# a31g22x register map
Vendor: ABOV Semiconductor Co., Ltd.; Series: a31g22x; File version: 0.2
CPU: CM0PLUS r0p1, little endian, no MPU, no FPU, VTOR, 2 interrupt priority bits
Registers are 32-bit, read-write, reset 0x0 unless marked. A register's access mark holds for its fields unless they carry their own. Offsets are from the block's base; [hi:lo] are bit positions; {n}, {i} and the like mark numbered series.

## SCULV — Low Voltage Detector Indicator and Reset moudle
Base 0x40005100
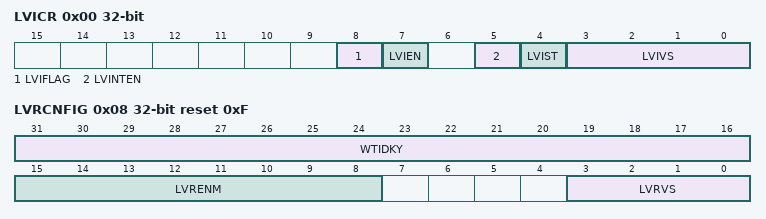
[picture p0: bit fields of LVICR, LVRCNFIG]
0x00 LVICR (reset mask 0xBF) — Low Voltage Indicator Control Register
  [8] LVIFLAG — LVI Interrupt Flag bit. This bit is clear by writing '1' to this bit.
  [7] LVIEN — LVI Enable bit
  [5] LVINTEN — LVI Interrupt Enable bit
  [4] LVIST ro — LVI Interrupt Status Flag bit. This bit is cleared to '0' when VDDEXT level is over than LVI level.
  [3:0] LVIVS — LVI Voltage Selection bits
0x04 LVRCR — Low Voltage Reset Control Register
  [7:0] LVREN — LVR Enable bits. These bits are cleared to 0x0 by POR and retained by other reset signals.
0x08 LVRCNFIG reset 0xF — Configuration for Low Voltage Reset
  [31:16] WTIDKY wo — Write Identification Key On writes, write 0x72A5 to these bits, otherwise the write is ignored.
  [15:8] LVRENM — LVR Reset Operation Control Master Configuration
  [3:0] LVRVS — LVR Voltage Selection bits

## PA — GENERAL PORT
Base 0x40001000
Same registers: PB 0x40001100, PC 0x40001200, PD 0x40001300, PE 0x40001400
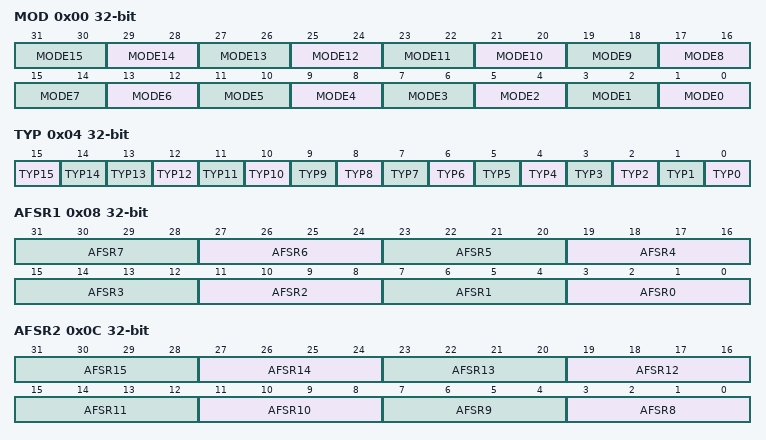
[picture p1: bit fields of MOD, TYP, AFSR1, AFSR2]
0x00 MOD — Port n Mode Register
  [2n+1:2n] MODE{n} (n=0..15) — Pin {n} Mode Selection bits
0x04 TYP — Port n Output Type Selection Register
  [15] TYP15 — Pin 15 Output Type Selection bit
  [14] TYP14 — Pin 15 Output Type Selection bit
  [n] TYP{n} (n=0..13) — Pin {n} Output Type Selection bit
0x08 AFSR1 — Port n Alternative Function Selection Register 1
  [4n+3:4n] AFSR{n} (n=0..7) — Pin {n} Alternative Function Selection bits
0x0C AFSR2 — Port n Alternative Function Selection Register 2
  [4n-29:4n-32] AFSR{n} (n=8..15) — Pin {n} Alternative Function Selection bits
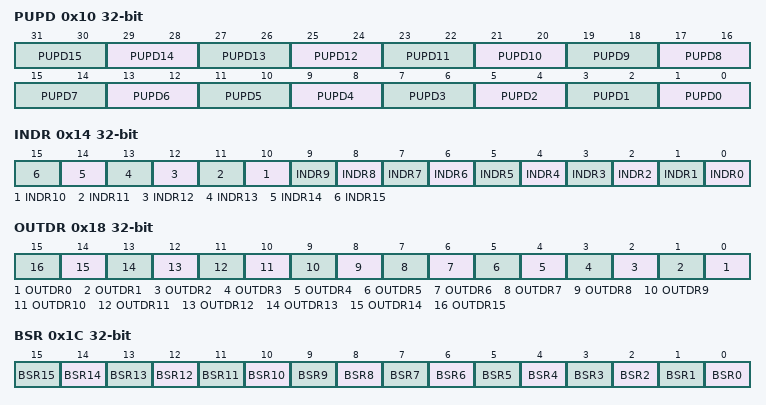
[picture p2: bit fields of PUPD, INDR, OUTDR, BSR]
0x10 PUPD — Port n Pull-up/down Resistor Selection Register
  [2n+1:2n] PUPD{n} (n=0..15) — Pin {n} Pull-up/down Resistor Selection bits
0x14 INDR ro — Port n Input Data Register
  [n] INDR{n} (n=0..15) — Pin {n} Input Data bit
0x18 OUTDR — Port n Output Data Register
  [n] OUTDR{n} (n=0..15) — Pin {n} Output Data bit
0x1C BSR wo — Port n Output Bit Set Register
  [n] BSR{n} (n=0..15) — Pin {n} Output Set bit. This bit is always read to 0
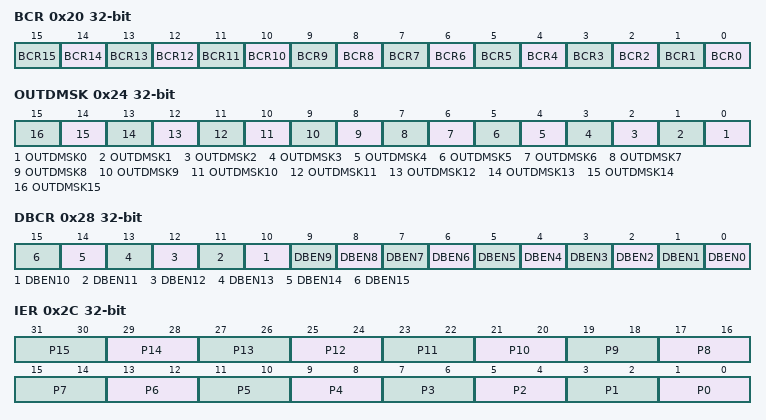
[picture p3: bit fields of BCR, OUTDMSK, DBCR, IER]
0x20 BCR wo — Port n Output Bit Clear Register
  [n] BCR{n} (n=0..15) — Pin {n} Output Clear bit. This bit is always read to 0.
0x24 OUTDMSK — Port n Output Data Mask Register
  [n] OUTDMSK{n} (n=0..15) — Pin {n} Output Data Mask bit
0x28 DBCR — Port n Debounce Control Register
  [n] DBEN{n} (n=0..15) — Pin {n} Debounce Enable bit
0x2C IER — Port n interrupt enable register
  [2n+1:2n] P{n} (n=0..15) — P{n} interrupt enable
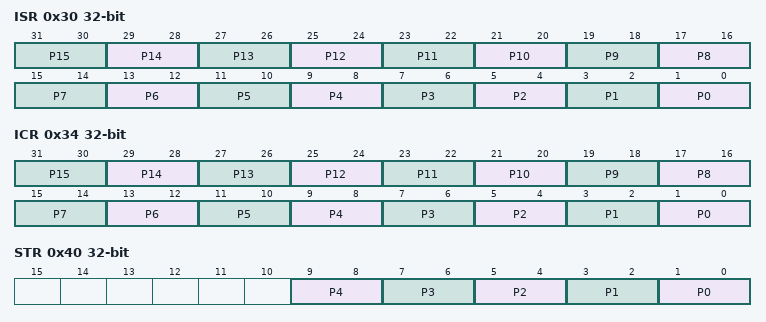
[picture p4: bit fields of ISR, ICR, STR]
0x30 ISR — Port n interrupt status register
  [2n+1:2n] P{n} (n=0..15) — P{n} interrupt status
0x34 ICR — Port n interrupt control register
  [2n+1:2n] P{n} (n=0..15) — P{n} interrupt control
0x40 STR — Port n Strength Configuration Register. This function is only valid for PB[2:0] and PC[4:2] ports.
  [2n+1:2n] P{n} (n=0..4) — P{n} Strength Configuration

## PF
Base 0x40001500
Registers as PA; these are added or differ:
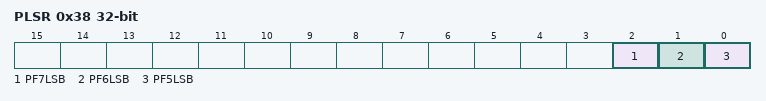
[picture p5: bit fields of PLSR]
0x38 PLSR — PORT F level select register
  [2] PF7LSB — PORTF 7 Level Select bit
  [1] PF6LSB — PORTF 6 Level Select bit
  [0] PF5LSB — PORTF 5 Level Select bit

## PCU1 — PORT CONTROL UNIT 1
Base 0x40001544
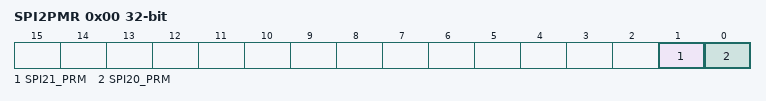
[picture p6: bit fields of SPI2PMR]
0x00 SPI2PMR — Port SPI2n Pin Re-Map Register
  [1] SPI21_PRM — Enable Pin Re-map of SPI21 channel
  [0] SPI20_PRM — Enable Pin Re-map of SPI20 channel

## PCU2 — PORT CONTROL UNIT 2
Base 0x40001F00
0x00 ISEGPEN — Port LED ISEG Port Enable Register
  [15:0] ISEGENKEY — Write 0x0702 to the operation key register for operating each of the ISEG and the inverted ISEG output ports
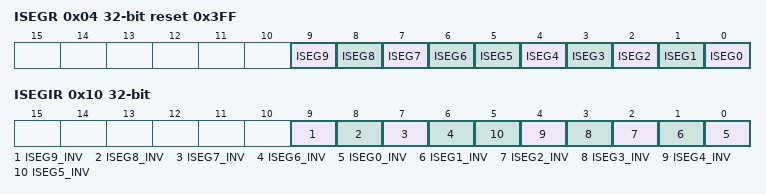
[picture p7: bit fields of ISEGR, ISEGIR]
0x04 ISEGR reset 0x3FF — Port LED ISEG Register
  [9] ISEG9 — LED ISEG9 singal control of PD2 port
  [8] ISEG8 — LED ISEG8 singal control of PD3 port
  [7] ISEG7 — LED ISEG7 singal control of PD4 port
  [6] ISEG6 — LED ISEG6 singal control of PD5 port
  [n] ISEG{n} (n=0..5) — LED ISEG{n} singal control of PE{n+2} port
0x10 ISEGIR — Port LED ISEG Inversion Register
  [9] ISEG9_INV — LED ISEG9 inverted singal control of PD2 port
  [8] ISEG8_INV — LED ISEG8 inverted singal control of PD3 port
  [7] ISEG7_INV — LED ISEG7 inverted singal control of PD4 port
  [6] ISEG6_INV — LED ISEG6 inverted singal control of PD5 port
  [n] ISEG{n}_INV (n=0..5) — LED ISEG{n} inverted singal control of PE{n+2} port
0xF0 PORTEN wo reset not defined — Port Access Enable Register
  [7:0] PORTEN — Writing the sequence of 0x15 and 0x51 in this register enables writing to PCU registers, and writing other values protects all PCU registers from writing

## Notices in the file
Copyright (C) 2012-2014 ARM Limited. All rights reserved.
Purpose: System Viewer Description (SVD) Example (Schema Version 1.1)
This is a description of a none-existent and incomplete device
for demonstration purposes only.
Redistribution and use in source and binary forms, with or without
modification, are permitted provided that the following conditions are met:
- Redistributions of source code must retain the above copyright
notice, this list of conditions and the following disclaimer.
- Redistributions in binary form must reproduce the above copyright
notice, this list of conditions and the following disclaimer in the
documentation and/or other materials provided with the distribution.
- Neither the name of ARM nor the names of its contributors may be used
to endorse or promote products derived from this software without
specific prior written permission.
THIS SOFTWARE IS PROVIDED BY THE COPYRIGHT HOLDERS AND CONTRIBUTORS "AS IS"
AND ANY EXPRESS OR IMPLIED WARRANTIES, INCLUDING, BUT NOT LIMITED TO, THE
IMPLIED WARRANTIES OF MERCHANTABILITY AND FITNESS FOR A PARTICULAR PURPOSE
ARE DISCLAIMED. IN NO EVENT SHALL COPYRIGHT HOLDERS AND CONTRIBUTORS BE
LIABLE FOR ANY DIRECT, INDIRECT, INCIDENTAL, SPECIAL, EXEMPLARY, OR
CONSEQUENTIAL DAMAGES (INCLUDING, BUT NOT LIMITED TO, PROCUREMENT OF
SUBSTITUTE GOODS OR SERVICES; LOSS OF USE, DATA, OR PROFITS; OR BUSINESS
INTERRUPTION) HOWEVER CAUSED AND ON ANY THEORY OF LIABILITY, WHETHER IN
CONTRACT, STRICT LIABILITY, OR TORT (INCLUDING NEGLIGENCE OR OTHERWISE)
ARISING IN ANY WAY OUT OF THE USE OF THIS SOFTWARE, EVEN IF ADVISED OF THE
POSSIBILITY OF SUCH DAMAGE.
